AUTOSAR XML (schema 00053)
package /MICROSAR/WdgM_swc
  mode declaration group WdgM_Mode: category=EXPLICIT_ORDER, initial-mode=SUPERVISION_OK, on-transition-value=255  # The mode declaration group WdgMMode represents the modes of the Watchdog Manager module that will be notified to the SW-Cs / CDDs and the RTE.
    5 x mode:
      SUPERVISION_OK: value=0
      SUPERVISION_FAILED: value=1
      SUPERVISION_EXPIRED: value=2
      SUPERVISION_STOPPED: value=3
      SUPERVISION_DEACTIVATED: value=4
  data type mapping set WdgMMappingSet: mode-request-type-map{implementation-data-type=WdgMMode, mode-group=WdgM_Mode}  # Contains mapping for mode declaration groups which are provided by WdgM.
package /MICROSAR/WdgM_swc/DataTypes
  6 x impl type, all with category=TYPE_REFERENCE:
    WdgM_SupervisedEntityIdType: range raw 0..65535, implementation-data-type=uint16  # Identifier of a supervised entity
    WdgM_CheckpointIdType: range raw 0..65535, implementation-data-type=uint16  # Identifier of a checkpoint
    WdgM_ModeType: range raw 0..255, implementation-data-type=uint8  # Identifier of the Watchdog trigger mode
    WdgM_LocalStatusType: compu {0=WDGM_LOCAL_STATUS_OK, 1=WDGM_LOCAL_STATUS_FAILED, 2=WDGM_LOCAL_STATUS_EXPIRED, 4=WDGM_LOCAL_STATUS_DEACTIVATED}, range raw 0..4, implementation-data-type=uint8  # Local Monitoring Status of a supervised entity.
    WdgM_GlobalStatusType: compu {0=WDGM_GLOBAL_STATUS_OK, 1=WDGM_GLOBAL_STATUS_FAILED, 2=WDGM_GLOBAL_STATUS_EXPIRED, 3=WDGM_GLOBAL_STATUS_STOPPED, 4=WDGM_GLOBAL_STATUS_DEACTIVATED}, range raw 0..4, implementation-data-type=uint8  # Global Monitoring Status summarizes all local monitoring statuses of all supervised entities.
    WdgMMode: compu {0=SUPERVISION_OK, 1=SUPERVISION_FAILED, 2=SUPERVISION_EXPIRED, 3=SUPERVISION_STOPPED, 4=SUPERVISION_DEACTIVATED}, range raw 0..255, implementation-data-type=uint8  # The implementation data type to be mapped to the mode declaration group.
package /MICROSAR/WdgM_swc/Interfaces
  client server interface WdgM_AliveSupervision: is-service=true, service-kind=WATCH-DOG-MANAGER
    operation CheckpointReached: possible-error=WdgM_AliveSupervision/E_NOT_OK  # Indicates to the Watchdog Manager that a Checkpoint within a Supervised Entity has been reached.
      arg CPID: type=WdgM_CheckpointIdType, direction=IN  # Identifier of the checkpoint within a supervised entity that has been reached.
    error E_NOT_OK: error-code=1
  client server interface WdgM_LocalStatus: is-service=true, service-kind=WATCH-DOG-MANAGER
    operation GetLocalStatus: possible-error=WdgM_LocalStatus/E_NOT_OK  # Returns the supervision status of a supervised entity.
      arg Status: type=WdgM_LocalStatusType, direction=OUT  # Supervision status of the given supervised entity.
    error E_NOT_OK: error-code=1
  client server interface WdgM_General: is-service=true, service-kind=WATCH-DOG-MANAGER
    8 x operation, all with possible-error=WdgM_General/E_NOT_OK:
      GetMode  # Returns the current mode of the Watchdog Manager.
        arg Mode: type=WdgM_ModeType, direction=OUT  # Current mode of the Watchdog Manager.
      GetGlobalStatus  # Returns the global supervision status of the Watchdog Manager.
        arg Status: type=WdgM_GlobalStatusType, direction=OUT  # Global supervision status of the Watchdog Manager.
      GetLocalStatus  # Returns the supervision status of a supervised entity.
        arg SEID: type=WdgM_SupervisedEntityIdType, direction=IN  # Identifier of the supervised entity whose supervision status shall be returned.
        arg Status: type=WdgM_LocalStatusType, direction=OUT  # Supervision status of the given supervised entity.
      PerformReset  # Instructs the Watchdog Manager to cause a watchdog reset.
      SetMode  # Requests a new trigger mode
        arg Mode: type=WdgM_ModeType, direction=IN  # Desired new trigger mode id.
        arg CallerID: type=uint16, direction=IN  # Module ID of the calling module.
      GetFirstExpiredSEID  # Returns the id of that supervised entity which first reached the status WDGM_LOCAL_STATUS_EXPIRED.
        arg SEID: type=WdgM_SupervisedEntityIdType, direction=OUT  # Pointer to a variable that stores the id of the supervised entity.
      ActivateSupervisionEntity  # Activates the supervision of the given supervised entity.
        arg SEID: type=WdgM_SupervisedEntityIdType, direction=IN  # Identifier of the supervised entity whose supervision shall be enabled.
      DeactivateSupervisionEntity  # Deactivates the supervision of the given supervised entity.
        arg SEID: type=WdgM_SupervisedEntityIdType, direction=IN  # Identifier of the supervised entity whose supervision shall be disenabled.
    error E_NOT_OK: error-code=1
  mode switch interface WdgM_IndividualMode: is-service=true, service-kind=WATCH-DOG-MANAGER  # The interface WdgM_IndividualMode is used to signal the local supervision status of a single supervised entity.
    mode group currentMode: type=WdgM_Mode
  mode switch interface WdgM_GlobalMode: is-service=true, service-kind=WATCH-DOG-MANAGER  # The interface WdgM_GlobalMode is used to signal the global supervision status that is combined from all individual supervised entities.
    mode group currentMode: type=WdgM_Mode
package /MICROSAR/WdgM_swc/ComponentTypes
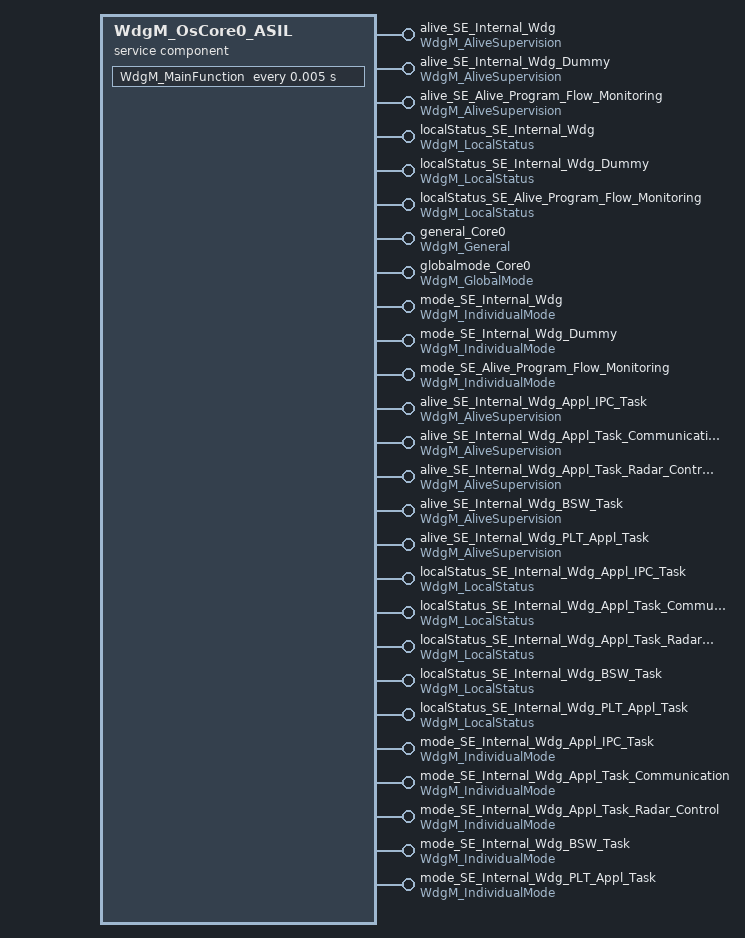
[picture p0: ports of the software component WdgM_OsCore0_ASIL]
  service sw component type WdgM_OsCore0_ASIL: category=SERVICE_COMPONENT
    26 x provide port:
      alive_SE_Internal_Wdg: provided-interface=WdgM_AliveSupervision  # Alive-P-Port Prototype for supervised entity 'SE_Internal_Wdg' with Id '1' for Application 'OsCore0_ASIL'.
      alive_SE_Internal_Wdg_Dummy: provided-interface=WdgM_AliveSupervision  # Alive-P-Port Prototype for supervised entity 'SE_Internal_Wdg_Dummy' with Id '0' for Application 'OsCore0_ASIL'.
      alive_SE_Alive_Program_Flow_Monitoring: provided-interface=WdgM_AliveSupervision  # Alive-P-Port Prototype for supervised entity 'SE_Alive_Program_Flow_Monitoring' with Id '2' for Application 'OsCore0_ASIL'.
      localStatus_SE_Internal_Wdg: provided-interface=WdgM_LocalStatus  # P-Port Prototype for supervised entity 'SE_Internal_Wdg' with Id '1' for Application 'OsCore0_ASIL' to request the local status.
      localStatus_SE_Internal_Wdg_Dummy: provided-interface=WdgM_LocalStatus  # P-Port Prototype for supervised entity 'SE_Internal_Wdg_Dummy' with Id '0' for Application 'OsCore0_ASIL' to request the local status.
      localStatus_SE_Alive_Program_Flow_Monitoring: provided-interface=WdgM_LocalStatus  # P-Port Prototype for supervised entity 'SE_Alive_Program_Flow_Monitoring' with Id '2' for Application 'OsCore0_ASIL' to request the local status.
      general_Core0: provided-interface=WdgM_General  # General P-Port-Prototype for core 0 (OsCore0_ASIL)
      globalmode_Core0: mode-switch-sender-com-spec=WdgM_GlobalMode/currentMode, provided-interface=WdgM_GlobalMode  # Mode port for reporting the global supervision status of WdgMMode of core 0
      mode_SE_Internal_Wdg: mode-switch-sender-com-spec=WdgM_IndividualMode/currentMode, provided-interface=WdgM_IndividualMode  # Mode port for reporting the local supervision status of SE_Internal_Wdg
      mode_SE_Internal_Wdg_Dummy: mode-switch-sender-com-spec=WdgM_IndividualMode/currentMode, provided-interface=WdgM_IndividualMode  # Mode port for reporting the local supervision status of SE_Internal_Wdg_Dummy
      mode_SE_Alive_Program_Flow_Monitoring: mode-switch-sender-com-spec=WdgM_IndividualMode/currentMode, provided-interface=WdgM_IndividualMode  # Mode port for reporting the local supervision status of SE_Alive_Program_Flow_Monitoring
      alive_SE_Internal_Wdg_Appl_IPC_Task: provided-interface=WdgM_AliveSupervision  # Alive-P-Port Prototype for supervised entity 'SE_Internal_Wdg_Appl_IPC_Task' with Id '3' for Application 'OsCore0_ASIL'.
      alive_SE_Internal_Wdg_Appl_Task_Communication: provided-interface=WdgM_AliveSupervision  # Alive-P-Port Prototype for supervised entity 'SE_Internal_Wdg_Appl_Task_Communication' with Id '5' for Application 'OsCore0_ASIL'.
      alive_SE_Internal_Wdg_Appl_Task_Radar_Control: provided-interface=WdgM_AliveSupervision  # Alive-P-Port Prototype for supervised entity 'SE_Internal_Wdg_Appl_Task_Radar_Control' with Id '6' for Application 'OsCore0_ASIL'.
      alive_SE_Internal_Wdg_BSW_Task: provided-interface=WdgM_AliveSupervision  # Alive-P-Port Prototype for supervised entity 'SE_Internal_Wdg_BSW_Task' with Id '7' for Application 'OsCore0_ASIL'.
      alive_SE_Internal_Wdg_PLT_Appl_Task: provided-interface=WdgM_AliveSupervision  # Alive-P-Port Prototype for supervised entity 'SE_Internal_Wdg_PLT_Appl_Task' with Id '4' for Application 'OsCore0_ASIL'.
      localStatus_SE_Internal_Wdg_Appl_IPC_Task: provided-interface=WdgM_LocalStatus  # P-Port Prototype for supervised entity 'SE_Internal_Wdg_Appl_IPC_Task' with Id '3' for Application 'OsCore0_ASIL' to request the local status.
      localStatus_SE_Internal_Wdg_Appl_Task_Communication: provided-interface=WdgM_LocalStatus  # P-Port Prototype for supervised entity 'SE_Internal_Wdg_Appl_Task_Communication' with Id '5' for Application 'OsCore0_ASIL' to request the local status.
      localStatus_SE_Internal_Wdg_Appl_Task_Radar_Control: provided-interface=WdgM_LocalStatus  # P-Port Prototype for supervised entity 'SE_Internal_Wdg_Appl_Task_Radar_Control' with Id '6' for Application 'OsCore0_ASIL' to request the local status.
      localStatus_SE_Internal_Wdg_BSW_Task: provided-interface=WdgM_LocalStatus  # P-Port Prototype for supervised entity 'SE_Internal_Wdg_BSW_Task' with Id '7' for Application 'OsCore0_ASIL' to request the local status.
      localStatus_SE_Internal_Wdg_PLT_Appl_Task: provided-interface=WdgM_LocalStatus  # P-Port Prototype for supervised entity 'SE_Internal_Wdg_PLT_Appl_Task' with Id '4' for Application 'OsCore0_ASIL' to request the local status.
      mode_SE_Internal_Wdg_Appl_IPC_Task: mode-switch-sender-com-spec=WdgM_IndividualMode/currentMode, provided-interface=WdgM_IndividualMode  # Mode port for reporting the local supervision status of SE_Internal_Wdg_Appl_IPC_Task
      mode_SE_Internal_Wdg_Appl_Task_Communication: mode-switch-sender-com-spec=WdgM_IndividualMode/currentMode, provided-interface=WdgM_IndividualMode  # Mode port for reporting the local supervision status of SE_Internal_Wdg_Appl_Task_Communication
      mode_SE_Internal_Wdg_Appl_Task_Radar_Control: mode-switch-sender-com-spec=WdgM_IndividualMode/currentMode, provided-interface=WdgM_IndividualMode  # Mode port for reporting the local supervision status of SE_Internal_Wdg_Appl_Task_Radar_Control
      mode_SE_Internal_Wdg_BSW_Task: mode-switch-sender-com-spec=WdgM_IndividualMode/currentMode, provided-interface=WdgM_IndividualMode  # Mode port for reporting the local supervision status of SE_Internal_Wdg_BSW_Task
      mode_SE_Internal_Wdg_PLT_Appl_Task: mode-switch-sender-com-spec=WdgM_IndividualMode/currentMode, provided-interface=WdgM_IndividualMode  # Mode port for reporting the local supervision status of SE_Internal_Wdg_PLT_Appl_Task
    behavior WdgM_OsCore0_ASILInternalBehavior: data-type-mapping=WdgMMappingSet, handle-termination-and-restart=NO-SUPPORT
      timing event Timer_WdgM_MainFunction: start-on-event=WdgM_MainFunction, period=0.005
      24 x operation invoked event:
        OpEventCheckpointReached_CheckpointReached_alive_SE_Internal_Wdg: start-on-event=CheckpointReached, operation=alive_SE_Internal_Wdg.CheckpointReached
        OpEventCheckpointReached_CheckpointReached_alive_SE_Internal_Wdg_Dummy: start-on-event=CheckpointReached, operation=alive_SE_Internal_Wdg_Dummy.CheckpointReached
        OpEventCheckpointReached_CheckpointReached_alive_SE_Alive_Program_Flow_Monitoring: start-on-event=CheckpointReached, operation=alive_SE_Alive_Program_Flow_Monitoring.CheckpointReached
        OpEventGetLocalStatus_GetLocalStatus_localStatus_SE_Internal_Wdg: start-on-event=GetLocalStatus, operation=localStatus_SE_Internal_Wdg.GetLocalStatus
        OpEventGetLocalStatus_GetLocalStatus_localStatus_SE_Internal_Wdg_Dummy: start-on-event=GetLocalStatus, operation=localStatus_SE_Internal_Wdg_Dummy.GetLocalStatus
        OpEventGetLocalStatus_GetLocalStatus_localStatus_SE_Alive_Program_Flow_Monitoring: start-on-event=GetLocalStatus, operation=localStatus_SE_Alive_Program_Flow_Monitoring.GetLocalStatus
        OpEventGetLocalStatus_GetLocalStatus_general_Core0: start-on-event=GetLocalStatus, operation=general_Core0.GetLocalStatus
        OpEventGetMode_GetMode_general_Core0: start-on-event=GetMode, operation=general_Core0.GetMode
        OpEventGetGlobalStatus_GetGlobalStatus_general_Core0: start-on-event=GetGlobalStatus, operation=general_Core0.GetGlobalStatus
        OpEventPerformReset_PerformReset_general_Core0: start-on-event=PerformReset, operation=general_Core0.PerformReset
        OpEventSetMode_SetMode_general_Core0: start-on-event=SetMode, operation=general_Core0.SetMode
        OpEventGetFirstExpiredSEID_GetFirstExpiredSEID_general_Core0: start-on-event=GetFirstExpiredSEID, operation=general_Core0.GetFirstExpiredSEID
        OpEventActivateSupervisionEntity_ActivateSupervisionEntity_general_Core0: start-on-event=ActivateSupervisionEntity, operation=general_Core0.ActivateSupervisionEntity
        OpEventDeactivateSupervisionEntity_DeactivateSupervisionEntity_general_Core0: start-on-event=DeactivateSupervisionEntity, operation=general_Core0.DeactivateSupervisionEntity
        OpEventCheckpointReached_CheckpointReached_alive_SE_Internal_Wdg_Appl_IPC_Task: start-on-event=CheckpointReached, operation=alive_SE_Internal_Wdg_Appl_IPC_Task.CheckpointReached
        OpEventCheckpointReached_CheckpointReached_alive_SE_Internal_Wdg_Appl_Task_Communication: start-on-event=CheckpointReached, operation=alive_SE_Internal_Wdg_Appl_Task_Communication.CheckpointReached
        OpEventCheckpointReached_CheckpointReached_alive_SE_Internal_Wdg_Appl_Task_Radar_Control: start-on-event=CheckpointReached, operation=alive_SE_Internal_Wdg_Appl_Task_Radar_Control.CheckpointReached
        OpEventCheckpointReached_CheckpointReached_alive_SE_Internal_Wdg_BSW_Task: start-on-event=CheckpointReached, operation=alive_SE_Internal_Wdg_BSW_Task.CheckpointReached
        OpEventCheckpointReached_CheckpointReached_alive_SE_Internal_Wdg_PLT_Appl_Task: start-on-event=CheckpointReached, operation=alive_SE_Internal_Wdg_PLT_Appl_Task.CheckpointReached
        OpEventGetLocalStatus_GetLocalStatus_localStatus_SE_Internal_Wdg_Appl_IPC_Task: start-on-event=GetLocalStatus, operation=localStatus_SE_Internal_Wdg_Appl_IPC_Task.GetLocalStatus
        OpEventGetLocalStatus_GetLocalStatus_localStatus_SE_Internal_Wdg_Appl_Task_Communication: start-on-event=GetLocalStatus, operation=localStatus_SE_Internal_Wdg_Appl_Task_Communication.GetLocalStatus
        OpEventGetLocalStatus_GetLocalStatus_localStatus_SE_Internal_Wdg_Appl_Task_Radar_Control: start-on-event=GetLocalStatus, operation=localStatus_SE_Internal_Wdg_Appl_Task_Radar_Control.GetLocalStatus
        OpEventGetLocalStatus_GetLocalStatus_localStatus_SE_Internal_Wdg_BSW_Task: start-on-event=GetLocalStatus, operation=localStatus_SE_Internal_Wdg_BSW_Task.GetLocalStatus
        OpEventGetLocalStatus_GetLocalStatus_localStatus_SE_Internal_Wdg_PLT_Appl_Task: start-on-event=GetLocalStatus, operation=localStatus_SE_Internal_Wdg_PLT_Appl_Task.GetLocalStatus
      port-api-options:
        {enable-take-address=true, indirect-api=false, port-defined-argument-value{value=SEID:1, value-type=WdgM_SupervisedEntityIdType}, port=alive_SE_Internal_Wdg}
        {enable-take-address=true, indirect-api=false, port-defined-argument-value{value=SEID:0, value-type=WdgM_SupervisedEntityIdType}, port=alive_SE_Internal_Wdg_Dummy}
        {enable-take-address=true, indirect-api=false, port-defined-argument-value{value=SEID:2, value-type=WdgM_SupervisedEntityIdType}, port=alive_SE_Alive_Program_Flow_Monitoring}
        {enable-take-address=true, indirect-api=false, port-defined-argument-value{value=1, value-type=WdgM_SupervisedEntityIdType}, port=localStatus_SE_Internal_Wdg}
        {enable-take-address=true, indirect-api=false, port-defined-argument-value{value=0, value-type=WdgM_SupervisedEntityIdType}, port=localStatus_SE_Internal_Wdg_Dummy}
        {enable-take-address=true, indirect-api=false, port-defined-argument-value{value=2, value-type=WdgM_SupervisedEntityIdType}, port=localStatus_SE_Alive_Program_Flow_Monitoring}
        enable-take-address=true, indirect-api=false, port=general_Core0
        enable-take-address=true, indirect-api=false, port=globalmode_Core0
        enable-take-address=true, indirect-api=false, port=mode_SE_Internal_Wdg
        enable-take-address=true, indirect-api=false, port=mode_SE_Internal_Wdg_Dummy
        enable-take-address=true, indirect-api=false, port=mode_SE_Alive_Program_Flow_Monitoring
        {enable-take-address=true, indirect-api=false, port-defined-argument-value{value=SEID:3, value-type=WdgM_SupervisedEntityIdType}, port=alive_SE_Internal_Wdg_Appl_IPC_Task}
        {enable-take-address=true, indirect-api=false, port-defined-argument-value{value=SEID:5, value-type=WdgM_SupervisedEntityIdType}, port=alive_SE_Internal_Wdg_Appl_Task_Communication}
        {enable-take-address=true, indirect-api=false, port-defined-argument-value{value=SEID:6, value-type=WdgM_SupervisedEntityIdType}, port=alive_SE_Internal_Wdg_Appl_Task_Radar_Control}
        {enable-take-address=true, indirect-api=false, port-defined-argument-value{value=SEID:7, value-type=WdgM_SupervisedEntityIdType}, port=alive_SE_Internal_Wdg_BSW_Task}
        {enable-take-address=true, indirect-api=false, port-defined-argument-value{value=SEID:4, value-type=WdgM_SupervisedEntityIdType}, port=alive_SE_Internal_Wdg_PLT_Appl_Task}
        {enable-take-address=true, indirect-api=false, port-defined-argument-value{value=3, value-type=WdgM_SupervisedEntityIdType}, port=localStatus_SE_Internal_Wdg_Appl_IPC_Task}
        {enable-take-address=true, indirect-api=false, port-defined-argument-value{value=5, value-type=WdgM_SupervisedEntityIdType}, port=localStatus_SE_Internal_Wdg_Appl_Task_Communication}
        {enable-take-address=true, indirect-api=false, port-defined-argument-value{value=6, value-type=WdgM_SupervisedEntityIdType}, port=localStatus_SE_Internal_Wdg_Appl_Task_Radar_Control}
        {enable-take-address=true, indirect-api=false, port-defined-argument-value{value=7, value-type=WdgM_SupervisedEntityIdType}, port=localStatus_SE_Internal_Wdg_BSW_Task}
        {enable-take-address=true, indirect-api=false, port-defined-argument-value{value=4, value-type=WdgM_SupervisedEntityIdType}, port=localStatus_SE_Internal_Wdg_PLT_Appl_Task}
        enable-take-address=true, indirect-api=false, port=mode_SE_Internal_Wdg_Appl_IPC_Task
        enable-take-address=true, indirect-api=false, port=mode_SE_Internal_Wdg_Appl_Task_Communication
        enable-take-address=true, indirect-api=false, port=mode_SE_Internal_Wdg_Appl_Task_Radar_Control
        enable-take-address=true, indirect-api=false, port=mode_SE_Internal_Wdg_BSW_Task
        enable-take-address=true, indirect-api=false, port=mode_SE_Internal_Wdg_PLT_Appl_Task
      10 x runnable, all with can-be-invoked-concurrently=true:
        WdgM_MainFunction
          9 x mode switch point:
            ModeSwitchPointWdgM_MainFunction_globalmode_Core0_currentMode: mode-group=globalmode_Core0.currentMode
            ModeSwitchPointWdgM_MainFunction_mode_SE_Internal_Wdg_currentMode: mode-group=mode_SE_Internal_Wdg.currentMode
            ModeSwitchPointWdgM_MainFunction_mode_SE_Internal_Wdg_Dummy_currentMode: mode-group=mode_SE_Internal_Wdg_Dummy.currentMode
            ModeSwitchPointWdgM_MainFunction_mode_SE_Alive_Program_Flow_Monitoring_currentMode: mode-group=mode_SE_Alive_Program_Flow_Monitoring.currentMode
            ModeSwitchPointWdgM_MainFunction_mode_SE_Internal_Wdg_Appl_IPC_Task_currentMode: mode-group=mode_SE_Internal_Wdg_Appl_IPC_Task.currentMode
            ModeSwitchPointWdgM_MainFunction_mode_SE_Internal_Wdg_Appl_Task_Communication_currentMode: mode-group=mode_SE_Internal_Wdg_Appl_Task_Communication.currentMode
            ModeSwitchPointWdgM_MainFunction_mode_SE_Internal_Wdg_Appl_Task_Radar_Control_currentMode: mode-group=mode_SE_Internal_Wdg_Appl_Task_Radar_Control.currentMode
            ModeSwitchPointWdgM_MainFunction_mode_SE_Internal_Wdg_BSW_Task_currentMode: mode-group=mode_SE_Internal_Wdg_BSW_Task.currentMode
            ModeSwitchPointWdgM_MainFunction_mode_SE_Internal_Wdg_PLT_Appl_Task_currentMode: mode-group=mode_SE_Internal_Wdg_PLT_Appl_Task.currentMode
        CheckpointReached: symbol=WdgM_CheckpointReached
        GetLocalStatus: symbol=WdgM_GetLocalStatus
        GetMode: symbol=WdgM_GetMode
        GetGlobalStatus: symbol=WdgM_GetGlobalStatus
        PerformReset: symbol=WdgM_PerformReset
        SetMode: symbol=WdgM_SetMode
        GetFirstExpiredSEID: symbol=WdgM_GetFirstExpiredSEID
        ActivateSupervisionEntity: symbol=WdgM_ActivateSupervisionEntity
        DeactivateSupervisionEntity: symbol=WdgM_DeactivateSupervisionEntity
  swc implementation WdgM_OsCore0_ASILImplementation: programming-language=C, behavior=WdgM_OsCore0_ASILInternalBehavior
